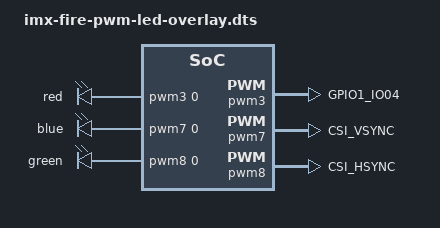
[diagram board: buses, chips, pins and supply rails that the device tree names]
/*
 * Copyright (C) 2019 - All Rights Reserved by 
 * filename : imx-fire-led-overlay.dts
 * brief : Device Tree overlay for EBF6ull led device
 * author : embedfire
 * date : 2019-11-15 
 * version : A001
 */
 /dts-v1/;
 /plugin/;
#include "../imx6ul-pinfunc.h"
#include "../imx6ull-pinfunc.h"
#include "dt-bindings/gpio/gpio.h"
 / {
        fragment@0 {
            target-path = "/";
            __overlay__ {
                pwm_leds{
                    compatible = "pwm-leds";
                    status = "okay";
                    red {
                        label = "red";
                        active-low;
                        pwms = <&pwm3 0 5000>;
                        max-brightness = <255>;                     
                    };

                    green {
                        label =  "blue";
                        active-low;
                        pwms = <&pwm7 0 5000>;
                        max-brightness = <255>;                      
                    };

                    blue {
                        label = "green";
                        active-low;
                        pwms = <&pwm8 0 5000>;
                        max-brightness = <255>;                         
                    };


                };
            };
        };

        fragment@1 {
            target= <&iomuxc>;
            __overlay__{
                pinctrl_pwm3:pwm3grp{
                    fsl,pins = < MX6UL_PAD_GPIO1_IO04__PWM3_OUT 0x000010B1 >;
                };
                pinctrl_pwm7:pwm7grp{
                    fsl,pins = < MX6UL_PAD_CSI_VSYNC__PWM7_OUT 0x000010B1 >;
                };

                pinctrl_pwm8:pwm8grp{
                    fsl,pins = <MX6UL_PAD_CSI_HSYNC__PWM8_OUT 0x000010B1 >;
                };
            };
        };

        fragment@2 {
            target= <&pwm3>;
            __overlay__ {
                pinctrl-names = "default";
                pinctrl-0 = <&pinctrl_pwm3>;
                status = "okay";               
            };
        };

        fragment@3 {
            target= <&pwm7>;
            __overlay__ {
                pinctrl-names = "default";
                pinctrl-0 = <&pinctrl_pwm7>;
                status = "okay";               
            };
        };

        fragment@4 {
            target= <&pwm8>;
            __overlay__ {
                pinctrl-names = "default";
                pinctrl-0 = <&pinctrl_pwm8>;
                status = "okay";               
            };
        };
 };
